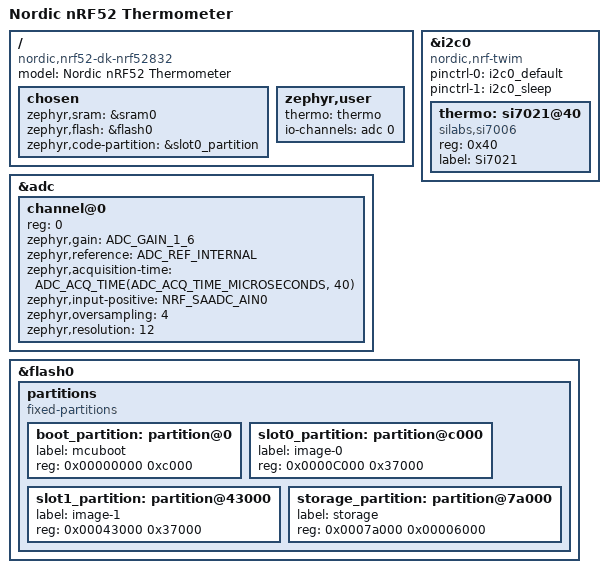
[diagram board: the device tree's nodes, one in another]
/*
 * Copyright (c) 2017 Shawn Nock <shawn@monadnock.ca>
 * Copyright (c) 2017 Linaro Limited
 *
 * SPDX-License-Identifier: Apache-2.0
 */

/dts-v1/;
#include <nordic/nrf52832_qfaa.dtsi>
#include "nrf52832_therm.dtsi"

/ {
	model = "Nordic nRF52 Thermometer";
	compatible = "nordic,nrf52-dk-nrf52832";

	chosen {
		zephyr,sram = &sram0;
		zephyr,flash = &flash0;
		zephyr,code-partition = &slot0_partition;
	};

	zephyr,user {
		thermo = <&thermo>;
		io-channels = <&adc 0>;
	};
};

&i2c0 {
	status = "okay";
	compatible = "nordic,nrf-twim";
	status = "okay";
	pinctrl-0 = <&i2c0_default>;
	pinctrl-1 = <&i2c0_sleep>;
	pinctrl-names = "default", "sleep";
	thermo: si7021@40{
		compatible = "silabs,si7006";
		reg = <0x40>;
		label = "Si7021";
		status = "okay";
	};
};

&adc {
	status = "okay";
	#address-cells = <1>;
	#size-cells = <0>;

	channel@0 {
		// when battery is not connected the jitter on the channel is quite high
		reg = <0>;
		zephyr,gain = "ADC_GAIN_1_6"; // nordic iref = 0.6v, i.e 4095 == 3.6v
		zephyr,reference = "ADC_REF_INTERNAL";
		zephyr,acquisition-time = <ADC_ACQ_TIME(ADC_ACQ_TIME_MICROSECONDS, 40)>; // slowest supported
		zephyr,input-positive = <NRF_SAADC_AIN0>; /* P0.02 */
		zephyr,oversampling = <4>; // average over 16 samples
		zephyr,resolution = <12>;
	};
};

&flash0 {

	partitions {
		compatible = "fixed-partitions";
		#address-cells = <1>;
		#size-cells = <1>;

		boot_partition: partition@0 {
			label = "mcuboot";
			reg = <0x00000000 0xc000>;
		};
		slot0_partition: partition@c000 {
			label = "image-0";
			reg = <0x0000C000 0x37000>;
		};
		slot1_partition: partition@43000 {
			label = "image-1";
			reg = <0x00043000 0x37000>;
		};
		storage_partition: partition@7a000 {
			label = "storage";
			reg = <0x0007a000 0x00006000>;
		};
	};
};
